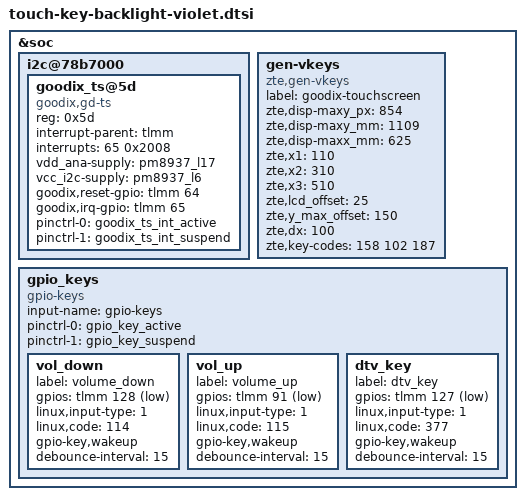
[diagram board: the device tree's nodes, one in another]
&soc {
	i2c@78b7000 { /* BLSP1 QUP5 */
		goodix_ts@5d {
				compatible = "goodix,gd-ts";
				reg = <0x5d>;
				interrupt-parent = <&tlmm>;
				interrupts = <65 0x2008>;
				vdd_ana-supply = <&pm8937_l17>;
				vcc_i2c-supply = <&pm8937_l6>;
				goodix,reset-gpio = <&tlmm 64 0x00>;
				goodix,irq-gpio = <&tlmm 65 0x00>;
				pinctrl-names = "default","sleep";
				pinctrl-0 = <&goodix_ts_int_active>;
				pinctrl-1 = <&goodix_ts_int_suspend>;
		};
	};

	gen-vkeys {
		compatible = "zte,gen-vkeys";
		label = "goodix-touchscreen";
		zte,disp-maxy_px = <854>;
		zte,disp-maxy_mm = <1109>;
		zte,disp-maxx_mm = <625>;
		zte,x1=<110>;
		zte,x2=<310>;
		zte,x3=<510>;
		zte,lcd_offset=<25>;
		zte,y_max_offset=<150>;
		zte,dx=<100>;
		zte,key-codes = <158 102 187>;
	};

	gpio_keys {
		compatible = "gpio-keys";
		input-name = "gpio-keys";
		pinctrl-names = "tlmm_gpio_key_active","tlmm_gpio_key_suspend";
		pinctrl-0 = <&gpio_key_active>;
		pinctrl-1 = <&gpio_key_suspend>;

		vol_down {
			label = "volume_down";
			gpios = <&tlmm 128 0x1>;
			linux,input-type = <1>;
			linux,code = <114>;
			gpio-key,wakeup;
			debounce-interval = <15>;
		};
		vol_up {
			label = "volume_up";
			gpios = <&tlmm 91 0x1>;
			linux,input-type = <1>;
			linux,code = <115>;
			gpio-key,wakeup;
			debounce-interval = <15>;
		};
		dtv_key {
			label = "dtv_key";
			gpios = <&tlmm 127 0x1>;
			linux,input-type = <1>;
			linux,code = <377>;
			gpio-key,wakeup;
			debounce-interval = <15>;
		};
	};

	/*gpio-leds {
		compatible = "gpio-leds";
		status = "okay";
		pinctrl-names = "default";
		pinctrl-0 = <&button_backlight_off>;

		keypad-backlight {
			gpios = <&tlmm 97 0>;
			label = "button-backlight";
			linux,default-trigger = "none";
		};
	};*/
};
